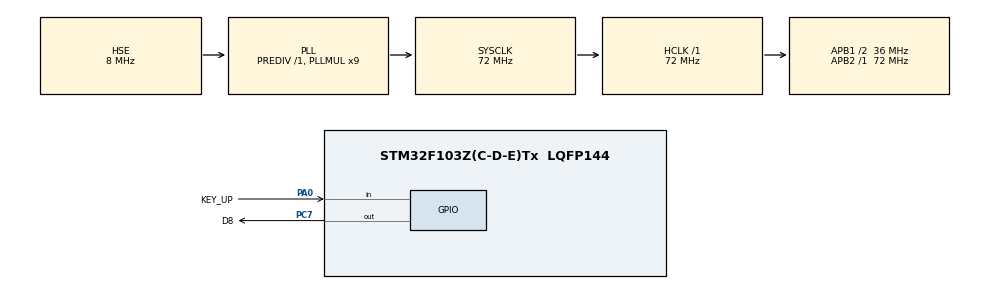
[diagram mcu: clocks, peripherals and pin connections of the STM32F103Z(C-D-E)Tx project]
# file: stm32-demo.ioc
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Mcu.Family=STM32F1
Mcu.Name=STM32F103Z(C-D-E)Tx
Mcu.Package=LQFP144
NVIC.PriorityGroup=NVIC_PRIORITYGROUP_4
OSC_IN.Mode=HSE-External-Oscillator
OSC_IN.Signal=RCC_OSC_IN
OSC_OUT.Mode=HSE-External-Oscillator
OSC_OUT.Signal=RCC_OSC_OUT
PA0-WKUP.GPIO_Label=KEY_UP
PA0-WKUP.GPIO_PuPd=GPIO_PULLDOWN
PA0-WKUP.Signal=GPIO_Input
PA13.Mode=Serial_Wire
PA13.Signal=SYS_JTMS-SWDIO
PA14.Mode=Serial_Wire
PA14.Signal=SYS_JTCK-SWCLK
PC7.GPIO_Label=D8
PC7.Signal=GPIO_Output
ProjectManager.HeapSize=0x200
ProjectManager.StackSize=0x400
ProjectManager.TargetToolchain=STM32CubeIDE
RCC.AHBFreq_Value=72000000
RCC.APB1CLKDivider=RCC_HCLK_DIV2
RCC.APB1Freq_Value=36000000
RCC.APB1TimFreq_Value=72000000
RCC.APB2Freq_Value=72000000
RCC.APB2TimFreq_Value=72000000
RCC.HCLKFreq_Value=72000000
RCC.PLLMUL=RCC_PLL_MUL9
RCC.PLLSourceVirtual=RCC_PLLSOURCE_HSE
RCC.SYSCLKFreq_VALUE=72000000
RCC.SYSCLKSource=RCC_SYSCLKSOURCE_PLLCLK
RCC.USBFreq_Value=72000000
board=custom

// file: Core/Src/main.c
/* USER CODE BEGIN Header */
/**
  ******************************************************************************
  * @file           : main.c
  * @brief          : Main program body
  ******************************************************************************
  * @attention
  *
  * Copyright (c) 2022 STMicroelectronics.
  * All rights reserved.
  *
  * This software is licensed under terms that can be found in the LICENSE file
  * in the root directory of this software component.
  * If no LICENSE file comes with this software, it is provided AS-IS.
  *
  ******************************************************************************
  */
/* USER CODE END Header */
#include "main.h"

/* USER CODE BEGIN PD */
// 把“位带地址+位序号”转换成别名地址的宏
#define BITBAND(addr, bitnum) ((addr & 0xF0000000)+0x2000000+((addr &0xFFFFF)<<5)+(bitnum<<2))
//  把一个地址转换成一个指针
#define MEM_ADDR(addr) *((volatile unsigned long *)(addr))
// 把位带别名区地址转换成指针
#define BIT_ADDR(addr, bitnum) MEM_ADDR(BITBAND(addr, bitnum))

//IO口输出寄存器地址映射
#define GPIOA_ODR_Addr    (GPIOA_BASE+12) //0x4001080C
#define GPIOB_ODR_Addr    (GPIOB_BASE+12) //0x40010C0C
#define GPIOC_ODR_Addr    (GPIOC_BASE+12) //0x4001100C
#define GPIOD_ODR_Addr    (GPIOD_BASE+12) //0x4001140C
#define GPIOE_ODR_Addr    (GPIOE_BASE+12) //0x4001180C
#define GPIOF_ODR_Addr    (GPIOF_BASE+12) //0x40011A0C
#define GPIOG_ODR_Addr    (GPIOG_BASE+12) //0x40011E0C
//IO口输入寄存器地址映射
#define GPIOA_IDR_Addr    (GPIOA_BASE+8) //0x40010808
#define GPIOB_IDR_Addr    (GPIOB_BASE+8) //0x40010C08
#define GPIOC_IDR_Addr    (GPIOC_BASE+8) //0x40011008
#define GPIOD_IDR_Addr    (GPIOD_BASE+8) //0x40011408
#define GPIOE_IDR_Addr    (GPIOE_BASE+8) //0x40011808
#define GPIOF_IDR_Addr    (GPIOF_BASE+8) //0x40011A08
#define GPIOG_IDR_Addr    (GPIOG_BASE+8) //0x40011E08

//IO口操作,只对单一的IO口!
//确保n的值为0~15
#define PAout(n)   BIT_ADDR(GPIOA_ODR_Addr,n)  //输出
#define PAin(n)    BIT_ADDR(GPIOA_IDR_Addr,n)  //输入

#define PBout(n)   BIT_ADDR(GPIOB_ODR_Addr,n)  //输出
#define PBin(n)    BIT_ADDR(GPIOB_IDR_Addr,n)  //输入

#define PCout(n)   BIT_ADDR(GPIOC_ODR_Addr,n)  //输出
#define PCin(n)    BIT_ADDR(GPIOC_IDR_Addr,n)  //输入

#define PDout(n)   BIT_ADDR(GPIOD_ODR_Addr,n)  //输出
#define PDin(n)    BIT_ADDR(GPIOD_IDR_Addr,n)  //输入

#define PEout(n)   BIT_ADDR(GPIOE_ODR_Addr,n)  //输出
#define PEin(n)    BIT_ADDR(GPIOE_IDR_Addr,n)  //输入

#define PFout(n)   BIT_ADDR(GPIOF_ODR_Addr,n)  //输出
#define PFin(n)    BIT_ADDR(GPIOF_IDR_Addr,n)  //输入

#define PGout(n)   BIT_ADDR(GPIOG_ODR_Addr,n)  //输出
#define PGin(n)    BIT_ADDR(GPIOG_IDR_Addr,n)  //输入

/* USER CODE END PD */

void SystemClock_Config(void);

static void MX_GPIO_Init(void);

int main(void) {

    /* MCU Configuration--------------------------------------------------------*/

    /* Reset of all peripherals, Initializes the Flash interface and the Systick. */
    HAL_Init();

    /* Configure the system clock */
    SystemClock_Config();

    /* Initialize all configured peripherals */
    MX_GPIO_Init();

    /* Infinite loop */
    while (1) {
        PCout(7) = PAin(0);
    }
}

void SystemClock_Config(void) {
    RCC_OscInitTypeDef RCC_OscInitStruct = {0};
    RCC_ClkInitTypeDef RCC_ClkInitStruct = {0};

    /** Initializes the RCC Oscillators according to the specified parameters
    * in the RCC_OscInitTypeDef structure.
    */
    RCC_OscInitStruct.OscillatorType = RCC_OSCILLATORTYPE_HSE;
    RCC_OscInitStruct.HSEState = RCC_HSE_ON;
    RCC_OscInitStruct.HSEPredivValue = RCC_HSE_PREDIV_DIV1;
    RCC_OscInitStruct.HSIState = RCC_HSI_ON;
    RCC_OscInitStruct.PLL.PLLState = RCC_PLL_ON;
    RCC_OscInitStruct.PLL.PLLSource = RCC_PLLSOURCE_HSE;
    RCC_OscInitStruct.PLL.PLLMUL = RCC_PLL_MUL9;
    if (HAL_RCC_OscConfig(&RCC_OscInitStruct) != HAL_OK) {
        Error_Handler();
    }

    /** Initializes the CPU, AHB and APB buses clocks
    */
    RCC_ClkInitStruct.ClockType = RCC_CLOCKTYPE_HCLK | RCC_CLOCKTYPE_SYSCLK
                                  | RCC_CLOCKTYPE_PCLK1 | RCC_CLOCKTYPE_PCLK2;
    RCC_ClkInitStruct.SYSCLKSource = RCC_SYSCLKSOURCE_PLLCLK;
    RCC_ClkInitStruct.AHBCLKDivider = RCC_SYSCLK_DIV1;
    RCC_ClkInitStruct.APB1CLKDivider = RCC_HCLK_DIV2;
    RCC_ClkInitStruct.APB2CLKDivider = RCC_HCLK_DIV1;

    if (HAL_RCC_ClockConfig(&RCC_ClkInitStruct, FLASH_LATENCY_2) != HAL_OK) {
        Error_Handler();
    }
}

static void MX_GPIO_Init(void) {
    GPIO_InitTypeDef GPIO_InitStruct = {0};

    /* GPIO Ports Clock Enable */
    __HAL_RCC_GPIOA_CLK_ENABLE();
    __HAL_RCC_GPIOC_CLK_ENABLE();

    /*Configure GPIO pin Output Level */
    HAL_GPIO_WritePin(D8_GPIO_Port, D8_Pin, GPIO_PIN_RESET);

    /*Configure GPIO pin : KEY_UP_Pin */
    GPIO_InitStruct.Pin = KEY_UP_Pin;
    GPIO_InitStruct.Mode = GPIO_MODE_INPUT;
    GPIO_InitStruct.Pull = GPIO_PULLDOWN;
    HAL_GPIO_Init(KEY_UP_GPIO_Port, &GPIO_InitStruct);

    /*Configure GPIO pin : D8_Pin */
    GPIO_InitStruct.Pin = D8_Pin;
    GPIO_InitStruct.Mode = GPIO_MODE_OUTPUT_PP;
    GPIO_InitStruct.Pull = GPIO_NOPULL;
    GPIO_InitStruct.Speed = GPIO_SPEED_FREQ_LOW;
    HAL_GPIO_Init(D8_GPIO_Port, &GPIO_InitStruct);

}

void Error_Handler(void) {
    __disable_irq();
    while (1) {
    }
}
